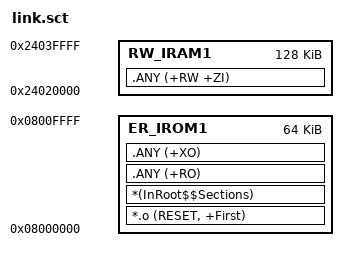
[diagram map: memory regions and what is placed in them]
; *************************************************************
; *** Scatter-Loading Description File generated by uVision ***
; *************************************************************

LR_IROM1 0x08000000 0x10000  {    ; load region size_region
  ER_IROM1 0x08000000 0x10000  {  ; load address = execution address
   *.o (RESET, +First)
   *(InRoot$$Sections)
   .ANY (+RO)
   .ANY (+XO)
  }
  RW_IRAM1 0x24020000 0x20000  {  ; AXI SRAM 128K
   .ANY (+RW +ZI)
  }
}
